VERSION ""

NS_ :

BS_:

BU_: PXI S32K144

BO_ 256 HIL_Vx: 8 PXI
 SG_ Vx : 0|16@1- (0.01,0) [0|327.67] "km/h" S32K144
 SG_ Cnt : 16|16@1+ (1,0) [0|65535] "" S32K144

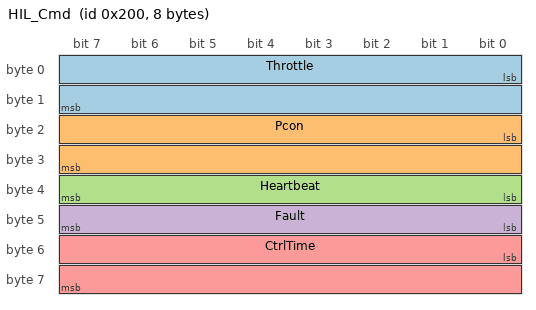
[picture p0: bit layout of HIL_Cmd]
BO_ 512 HIL_Cmd: 8 S32K144
 SG_ Throttle : 0|16@1+ (0.0001,0) [0|1] "" PXI
 SG_ Pcon : 16|16@1+ (0.001,0) [0|65.535] "MPa" PXI
 SG_ Heartbeat : 32|8@1+ (1,0) [0|255] "" PXI
 SG_ Fault : 40|8@1+ (1,0) [0|255] "" PXI
 SG_ CtrlTime : 48|16@1+ (0.001,0) [0|65.535] "ms" PXI

BA_DEF_ BO_ "GenMsgCycleTime" INT 0 65535;
BA_DEF_DEF_ "GenMsgCycleTime" 0;
BA_ "GenMsgCycleTime" BO_ 256 1;
BA_ "GenMsgCycleTime" BO_ 512 10;
